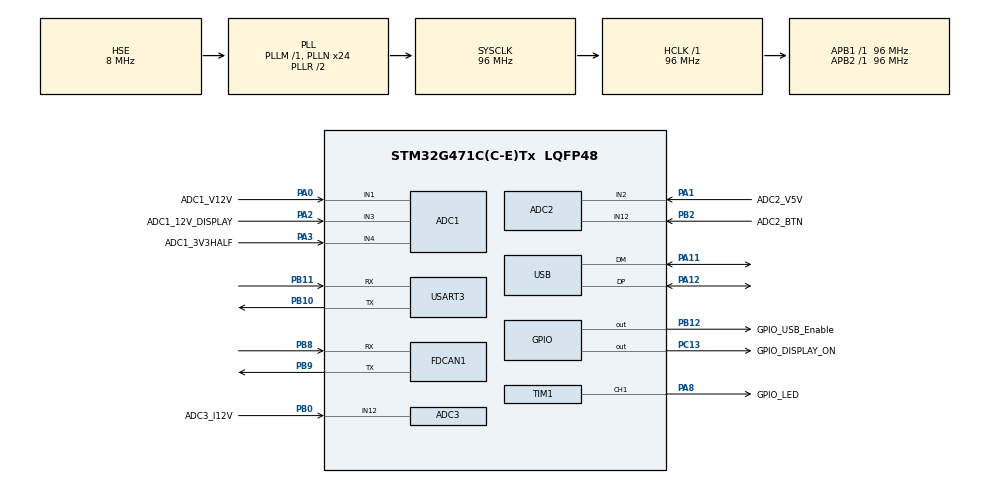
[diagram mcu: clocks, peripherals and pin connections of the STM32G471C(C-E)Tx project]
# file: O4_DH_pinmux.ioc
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ADC1.Channel-0\#ChannelRegularConversion=ADC_CHANNEL_1
ADC1.Channel-1\#ChannelRegularConversion=ADC_CHANNEL_3
ADC1.Channel-2\#ChannelRegularConversion=ADC_CHANNEL_4
ADC1.ClockPrescaler=ADC_CLOCK_ASYNC_DIV4
ADC1.ContinuousConvMode=DISABLE
ADC1.DMAContinuousRequests=ENABLE
ADC1.DataAlign=ADC_DATAALIGN_RIGHT
ADC1.EOCSelection=ADC_EOC_SINGLE_CONV
ADC1.ExternalTrigConv=ADC_EXTERNALTRIG_T1_TRGO
ADC1.ExternalTrigConvEdge=ADC_EXTERNALTRIGCONVEDGE_RISINGFALLING
ADC1.Mode=ADC_MODE_INDEPENDENT
ADC1.NbrOfConversion=3
ADC1.NbrOfConversionFlag=1
ADC1.OffsetNumber-0\#ChannelRegularConversion=ADC_OFFSET_NONE
ADC1.OffsetNumber-1\#ChannelRegularConversion=ADC_OFFSET_NONE
ADC1.OffsetNumber-2\#ChannelRegularConversion=ADC_OFFSET_NONE
ADC1.Overrun=ADC_OVR_DATA_OVERWRITTEN
ADC1.Rank-0\#ChannelRegularConversion=1
ADC1.Rank-1\#ChannelRegularConversion=2
ADC1.Rank-2\#ChannelRegularConversion=3
ADC1.SamplingTime-0\#ChannelRegularConversion=ADC_SAMPLETIME_92CYCLES_5
ADC1.SamplingTime-1\#ChannelRegularConversion=ADC_SAMPLETIME_92CYCLES_5
ADC1.SamplingTime-2\#ChannelRegularConversion=ADC_SAMPLETIME_92CYCLES_5
ADC1.master=1
ADC2.Channel-0\#ChannelRegularConversion=ADC_CHANNEL_2
ADC2.Channel-1\#ChannelRegularConversion=ADC_CHANNEL_12
ADC2.ClockPrescaler=ADC_CLOCK_ASYNC_DIV4
ADC2.ContinuousConvMode=DISABLE
ADC2.DMAContinuousRequests=ENABLE
ADC2.DataAlign=ADC_DATAALIGN_RIGHT
ADC2.EOCSelection=ADC_EOC_SINGLE_CONV
ADC2.ExternalTrigConv=ADC_EXTERNALTRIG_T1_TRGO
ADC2.ExternalTrigConvEdge=ADC_EXTERNALTRIGCONVEDGE_RISINGFALLING
ADC2.NbrOfConversion=2
ADC2.NbrOfConversionFlag=1
ADC2.OffsetNumber-0\#ChannelRegularConversion=ADC_OFFSET_NONE
ADC2.OffsetNumber-1\#ChannelRegularConversion=ADC_OFFSET_NONE
ADC2.Overrun=ADC_OVR_DATA_OVERWRITTEN
ADC2.Rank-0\#ChannelRegularConversion=1
ADC2.Rank-1\#ChannelRegularConversion=2
ADC2.SamplingTime-0\#ChannelRegularConversion=ADC_SAMPLETIME_92CYCLES_5
ADC2.SamplingTime-1\#ChannelRegularConversion=ADC_SAMPLETIME_92CYCLES_5
ADC3.Channel-0\#ChannelRegularConversion=ADC_CHANNEL_12
ADC3.Channel-1\#ChannelRegularConversion=ADC_CHANNEL_VBAT
ADC3.Channel-2\#ChannelRegularConversion=ADC_CHANNEL_VREFINT
ADC3.ClockPrescaler=ADC_CLOCK_ASYNC_DIV4
ADC3.ContinuousConvMode=DISABLE
ADC3.DMAContinuousRequests=ENABLE
ADC3.EOCSelection=ADC_EOC_SINGLE_CONV
ADC3.ExternalTrigConv=ADC_EXTERNALTRIG_T1_TRGO
ADC3.ExternalTrigConvEdge=ADC_EXTERNALTRIGCONVEDGE_RISINGFALLING
ADC3.NbrOfConversion=3
ADC3.NbrOfConversionFlag=1
ADC3.OffsetNumber-0\#ChannelRegularConversion=ADC_OFFSET_NONE
ADC3.OffsetNumber-1\#ChannelRegularConversion=ADC_OFFSET_NONE
ADC3.OffsetNumber-2\#ChannelRegularConversion=ADC_OFFSET_NONE
ADC3.Overrun=ADC_OVR_DATA_OVERWRITTEN
ADC3.Rank-0\#ChannelRegularConversion=1
ADC3.Rank-1\#ChannelRegularConversion=2
ADC3.Rank-2\#ChannelRegularConversion=3
ADC3.SamplingTime-0\#ChannelRegularConversion=ADC_SAMPLETIME_92CYCLES_5
ADC3.SamplingTime-1\#ChannelRegularConversion=ADC_SAMPLETIME_92CYCLES_5
ADC3.SamplingTime-2\#ChannelRegularConversion=ADC_SAMPLETIME_92CYCLES_5
ADC3.master=1
Dma.ADC1.0.Direction=DMA_PERIPH_TO_MEMORY
Dma.ADC1.0.EventEnable=ENABLE
Dma.ADC1.0.Instance=DMA1_Channel1
Dma.ADC1.0.MemDataAlignment=DMA_MDATAALIGN_HALFWORD
Dma.ADC1.0.MemInc=DMA_MINC_ENABLE
Dma.ADC1.0.Mode=DMA_CIRCULAR
Dma.ADC1.0.PeriphDataAlignment=DMA_PDATAALIGN_HALFWORD
Dma.ADC1.0.PeriphInc=DMA_PINC_DISABLE
Dma.ADC1.0.Polarity=HAL_DMAMUX_REQ_GEN_RISING
Dma.ADC1.0.Priority=DMA_PRIORITY_LOW
Dma.ADC1.0.RequestNumber=1
Dma.ADC1.0.SignalID=NONE
Dma.ADC1.0.SyncEnable=DISABLE
Dma.ADC1.0.SyncPolarity=HAL_DMAMUX_SYNC_NO_EVENT
Dma.ADC1.0.SyncRequestNumber=1
Dma.ADC1.0.SyncSignalID=NONE
Dma.ADC2.1.Direction=DMA_PERIPH_TO_MEMORY
Dma.ADC2.1.EventEnable=ENABLE
Dma.ADC2.1.Instance=DMA1_Channel2
Dma.ADC2.1.MemDataAlignment=DMA_MDATAALIGN_HALFWORD
Dma.ADC2.1.MemInc=DMA_MINC_ENABLE
Dma.ADC2.1.Mode=DMA_CIRCULAR
Dma.ADC2.1.PeriphDataAlignment=DMA_PDATAALIGN_HALFWORD
Dma.ADC2.1.PeriphInc=DMA_PINC_DISABLE
Dma.ADC2.1.Polarity=HAL_DMAMUX_REQ_GEN_RISING
Dma.ADC2.1.Priority=DMA_PRIORITY_LOW
Dma.ADC2.1.RequestNumber=1
Dma.ADC2.1.SignalID=NONE
Dma.ADC2.1.SyncEnable=DISABLE
Dma.ADC2.1.SyncPolarity=HAL_DMAMUX_SYNC_NO_EVENT
Dma.ADC2.1.SyncRequestNumber=1
Dma.ADC2.1.SyncSignalID=NONE
Dma.ADC3.2.Direction=DMA_PERIPH_TO_MEMORY
Dma.ADC3.2.EventEnable=DISABLE
Dma.ADC3.2.Instance=DMA1_Channel3
Dma.ADC3.2.MemDataAlignment=DMA_MDATAALIGN_HALFWORD
Dma.ADC3.2.MemInc=DMA_MINC_ENABLE
Dma.ADC3.2.Mode=DMA_CIRCULAR
Dma.ADC3.2.PeriphDataAlignment=DMA_PDATAALIGN_HALFWORD
Dma.ADC3.2.PeriphInc=DMA_PINC_DISABLE
Dma.ADC3.2.Polarity=HAL_DMAMUX_REQ_GEN_RISING
Dma.ADC3.2.Priority=DMA_PRIORITY_LOW
Dma.ADC3.2.RequestNumber=1
Dma.ADC3.2.SignalID=NONE
Dma.ADC3.2.SyncEnable=DISABLE
Dma.ADC3.2.SyncPolarity=HAL_DMAMUX_SYNC_NO_EVENT
Dma.ADC3.2.SyncRequestNumber=1
Dma.ADC3.2.SyncSignalID=NONE
Dma.Request0=ADC1
Dma.Request1=ADC2
Dma.Request2=ADC3
Mcu.Family=STM32G4
Mcu.Name=STM32G471C(C-E)Tx
Mcu.Package=LQFP48
NVIC.DMA1_Channel1_IRQn=true\:0\:0\:false\:false\:true\:false\:true
NVIC.DMA1_Channel2_IRQn=true\:0\:0\:false\:false\:true\:false\:true
NVIC.DMA1_Channel3_IRQn=true\:0\:0\:false\:false\:true\:false\:true
NVIC.DMAMUX_OVR_IRQn=true\:0\:0\:false\:false\:true\:false\:true
NVIC.PriorityGroup=NVIC_PRIORITYGROUP_4
NVIC.USB_LP_IRQn=true\:0\:0\:false\:false\:true\:false\:true
PA0.GPIO_Label=ADC1_V12V
PA0.Mode=IN1-Single-Ended
PA0.Signal=ADC1_IN1
PA1.GPIO_Label=ADC2_V5V
PA1.Mode=IN2-Single-Ended
PA1.Signal=ADC2_IN2
PA10.Signal=UCPD1_DBCC2
PA11.Mode=Device
PA11.Signal=USB_DM
PA12.Mode=Device
PA12.Signal=USB_DP
PA13.Mode=Trace_Asynchronous_SW
PA13.Signal=SYS_JTMS-SWDIO
PA14.Mode=Trace_Asynchronous_SW
PA14.Signal=SYS_JTCK-SWCLK
PA2.GPIO_Label=ADC1_12V_DISPLAY
PA2.Mode=IN3-Single-Ended
PA2.Signal=ADC1_IN3
PA3.GPIO_Label=ADC1_3V3HALF
PA3.Mode=IN4-Single-Ended
PA3.Signal=ADC1_IN4
PA8.GPIO_Label=GPIO_LED
PA8.Signal=S_TIM1_CH1
PA9.Signal=UCPD1_DBCC1
PB0.GPIO_Label=ADC3_I12V
PB0.Mode=IN12-Single-Ended
PB0.Signal=ADC3_IN12
PB10.Mode=Asynchronous
PB10.Signal=USART3_TX
PB11.Mode=Asynchronous
PB11.Signal=USART3_RX
PB12.GPIO_Label=GPIO_USB_Enable
PB12.Signal=GPIO_Output
PB2.GPIO_Label=ADC2_BTN
PB2.Mode=IN12-Single-Ended
PB2.Signal=ADC2_IN12
PB3.Mode=Trace_Asynchronous_SW
PB3.Signal=SYS_JTDO-SWO
PB4.Signal=UCPD1_CC2
PB6.Signal=UCPD1_CC1
PB8-BOOT0.Mode=FDCANFD
PB8-BOOT0.Signal=FDCAN1_RX
PB9.Mode=FDCANFD
PB9.Signal=FDCAN1_TX
PC13.GPIO_Label=GPIO_DISPLAY_ON
PC13.Signal=GPIO_Output
PF0-OSC_IN.Mode=HSE-External-Oscillator
PF0-OSC_IN.Signal=RCC_OSC_IN
PF1-OSC_OUT.Mode=HSE-External-Oscillator
PF1-OSC_OUT.Signal=RCC_OSC_OUT
ProjectManager.HeapSize=0x200
ProjectManager.StackSize=0x400
ProjectManager.TargetToolchain=STM32CubeIDE
RCC.ADC12CLockSelection=RCC_ADC12CLKSOURCE_PLL
RCC.ADC12Freq_Value=24000000
RCC.ADC345CLockSelection=RCC_ADC345CLKSOURCE_PLL
RCC.ADC345Freq_Value=24000000
RCC.AHBFreq_Value=96000000
RCC.APB1Freq_Value=96000000
RCC.APB1TimFreq_Value=96000000
RCC.APB2Freq_Value=96000000
RCC.APB2TimFreq_Value=96000000
RCC.CortexFreq_Value=96000000
RCC.EXTERNAL_CLOCK_VALUE=12288000
RCC.FDCANCLockSelection=RCC_FDCANCLKSOURCE_PLL
RCC.HCLKFreq_Value=96000000
RCC.HSE_VALUE=8000000
RCC.HSI48_VALUE=48000000
RCC.HSI_VALUE=16000000
RCC.LSE_VALUE=32768
RCC.PLLN=24
RCC.PLLP=RCC_PLLP_DIV8
RCC.PLLQ=RCC_PLLQ_DIV4
RCC.PLLSourceVirtual=RCC_PLLSOURCE_HSE
RCC.SYSCLKFreq_VALUE=96000000
RCC.SYSCLKSource=RCC_SYSCLKSOURCE_PLLCLK
RCC.USBFreq_Value=48000000
RCC.VCOOutputFreq_Value=192000000
SH.S_TIM1_CH1.0=TIM1_CH1,PWM Generation1 CH1
SYS.VoltageScaling=SYSCFG_VREFBUF_VOLTAGE_SCALE1
TIM1.AutoReloadPreload=TIM_AUTORELOAD_PRELOAD_ENABLE
TIM1.Channel-PWM\ Generation1\ CH1=TIM_CHANNEL_1
TIM1.CounterMode=TIM_COUNTERMODE_CENTERALIGNED1
TIM1.PeriodNoDither=7353
TIM1.Prescaler=32
TIM1.PulseNoDither_1=234
TIM1.TIM_MasterOutputTrigger=TIM_TRGO_UPDATE
TIM1.TIM_MasterOutputTrigger2=TIM_TRGO2_UPDATE
TIM1.TIM_MasterSlaveMode=TIM_MASTERSLAVEMODE_DISABLE
USART3.VirtualMode-Asynchronous=VM_ASYNC
USB_DEVICE.CLASS_NAME_FS=CDC
USB_DEVICE.VirtualMode=Cdc
USB_DEVICE.VirtualModeFS=Cdc_FS
VP_ADC3_Vbat_Input.Mode=IN-Vbat
VP_ADC3_Vref_Input.Mode=IN-Vrefint
VP_DAC1_VS_DACI1.Mode=DAC_OUT1_Int
VP_SYS_VS_DBSignals.Mode=DisableDeadBatterySignals
VP_TIM1_VS_ClockSourceINT.Mode=Internal
VP_USB_DEVICE_VS_USB_DEVICE_CDC_FS.Mode=CDC_FS
VREF+.Mode=InternalMode
VREF+.Signal=VREFBUF_OUT
board=custom

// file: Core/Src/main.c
/* USER CODE BEGIN Header */
/**
  ******************************************************************************
  * @file           : main.c
  * @brief          : Main program body
  ******************************************************************************
  * @attention
  *
  * <h2><center>&copy; Copyright (c) 2020 STMicroelectronics.
  * All rights reserved.</center></h2>
  *
  * This software component is licensed by ST under BSD 3-Clause license,
  * the "License"; You may not use this file except in compliance with the
  * License. You may obtain a copy of the License at:
  *                        opensource.org/licenses/BSD-3-Clause
  *
  ******************************************************************************
  */
/* USER CODE END Header */

#include "main.h"
#include "usb_device.h"
#include "adc.h"

ADC_HandleTypeDef hadc1;
ADC_HandleTypeDef hadc2;
ADC_HandleTypeDef hadc3;
DMA_HandleTypeDef hdma_adc1;
DMA_HandleTypeDef hdma_adc2;
DMA_HandleTypeDef hdma_adc3;

DAC_HandleTypeDef hdac1;

FDCAN_HandleTypeDef hfdcan1;

TIM_HandleTypeDef htim1;

UART_HandleTypeDef huart3;

void SystemClock_Config(void);
static void MX_GPIO_Init(void);
static void MX_DMA_Init(void);
static void MX_ADC1_Init(void);
static void MX_ADC2_Init(void);
static void MX_ADC3_Init(void);
static void MX_DAC1_Init(void);
static void MX_FDCAN1_Init(void);
static void MX_TIM1_Init(void);
static void MX_USART3_UART_Init(void);

/* USER CODE BEGIN 0 */

/* ToDo move later in separate file */
/* USER CODE END 0 */
void adc_start()
{
	if (HAL_ADCEx_Calibration_Start(&hadc1, ADC_SINGLE_ENDED) != HAL_OK)
	{
		Error_Handler();
	}
	if (HAL_ADCEx_Calibration_Start(&hadc2, ADC_SINGLE_ENDED) != HAL_OK)
	{
		Error_Handler();
	}
	if (HAL_ADCEx_Calibration_Start(&hadc3, ADC_SINGLE_ENDED) != HAL_OK)
	{
		Error_Handler();
	}
	HAL_Delay(100);
	HAL_ADC_Start_DMA(&hadc1, (uint32_t*)get_adc_raw_data(1,0), 3 );
	HAL_ADC_Start_DMA(&hadc2, (uint32_t*)get_adc_raw_data(2,0), 2 );
	HAL_ADC_Start_DMA(&hadc3, (uint32_t*)get_adc_raw_data(3,0), 3 );
}

int main(void)
{

  /* MCU Configuration--------------------------------------------------------*/

  /* Reset of all peripherals, Initializes the Flash interface and the Systick. */
  HAL_Init();

  /* USER CODE BEGIN Init */
  HAL_Delay(300); //delay after enable Vref
  /* USER CODE END Init */

  /* Configure the system clock */
  SystemClock_Config();

  /* Initialize all configured peripherals */
  MX_GPIO_Init();
  MX_DMA_Init();
  MX_ADC1_Init();
  MX_ADC2_Init();
  MX_ADC3_Init();
  MX_DAC1_Init();
  MX_FDCAN1_Init();
  MX_TIM1_Init();
  MX_USART3_UART_Init();
  MX_USB_Device_Init();
  /* USER CODE BEGIN 2 */
  /**/
  adc_start();
  /*## Start PWM signals generation #######################################*/
    /* Start channel 1 */
    if (HAL_TIM_PWM_Start(&htim1, TIM_CHANNEL_1) != HAL_OK)
    {
      /* PWM Generation Error */
      Error_Handler();
    }
    htim1.Instance->CCR1=7353/2;

  /* USER CODE END 2 */

  /* Infinite loop */
  /* USER CODE BEGIN WHILE */
    uint32_t i,s=0;
  while (1)
  {
	  i++;
	  s+=i;
    /* USER CODE END WHILE */

  }
}

void SystemClock_Config(void)
{
  RCC_OscInitTypeDef RCC_OscInitStruct = {0};
  RCC_ClkInitTypeDef RCC_ClkInitStruct = {0};
  RCC_PeriphCLKInitTypeDef PeriphClkInit = {0};

  /** Configure the main internal regulator output voltage
  */
  HAL_PWREx_ControlVoltageScaling(PWR_REGULATOR_VOLTAGE_SCALE1);
  /** Initializes the CPU, AHB and APB busses clocks
  */
  RCC_OscInitStruct.OscillatorType = RCC_OSCILLATORTYPE_HSE;
  RCC_OscInitStruct.HSEState = RCC_HSE_ON;
  RCC_OscInitStruct.PLL.PLLState = RCC_PLL_ON;
  RCC_OscInitStruct.PLL.PLLSource = RCC_PLLSOURCE_HSE;
  RCC_OscInitStruct.PLL.PLLM = RCC_PLLM_DIV1;
  RCC_OscInitStruct.PLL.PLLN = 24;
  RCC_OscInitStruct.PLL.PLLP = RCC_PLLP_DIV8;
  RCC_OscInitStruct.PLL.PLLQ = RCC_PLLQ_DIV4;
  RCC_OscInitStruct.PLL.PLLR = RCC_PLLR_DIV2;
  if (HAL_RCC_OscConfig(&RCC_OscInitStruct) != HAL_OK)
  {
    Error_Handler();
  }
  /** Initializes the CPU, AHB and APB busses clocks
  */
  RCC_ClkInitStruct.ClockType = RCC_CLOCKTYPE_HCLK|RCC_CLOCKTYPE_SYSCLK
                              |RCC_CLOCKTYPE_PCLK1|RCC_CLOCKTYPE_PCLK2;
  RCC_ClkInitStruct.SYSCLKSource = RCC_SYSCLKSOURCE_PLLCLK;
  RCC_ClkInitStruct.AHBCLKDivider = RCC_SYSCLK_DIV1;
  RCC_ClkInitStruct.APB1CLKDivider = RCC_HCLK_DIV1;
  RCC_ClkInitStruct.APB2CLKDivider = RCC_HCLK_DIV1;

  if (HAL_RCC_ClockConfig(&RCC_ClkInitStruct, FLASH_LATENCY_4) != HAL_OK)
  {
    Error_Handler();
  }
  /** Initializes the peripherals clocks
  */
  PeriphClkInit.PeriphClockSelection = RCC_PERIPHCLK_USART3|RCC_PERIPHCLK_USB
                              |RCC_PERIPHCLK_ADC12|RCC_PERIPHCLK_ADC345
                              |RCC_PERIPHCLK_FDCAN;
  PeriphClkInit.Usart3ClockSelection = RCC_USART3CLKSOURCE_PCLK1;
  PeriphClkInit.FdcanClockSelection = RCC_FDCANCLKSOURCE_PLL;
  PeriphClkInit.UsbClockSelection = RCC_USBCLKSOURCE_PLL;
  PeriphClkInit.Adc12ClockSelection = RCC_ADC12CLKSOURCE_PLL;
  PeriphClkInit.Adc345ClockSelection = RCC_ADC345CLKSOURCE_PLL;
  if (HAL_RCCEx_PeriphCLKConfig(&PeriphClkInit) != HAL_OK)
  {
    Error_Handler();
  }
}

static void MX_ADC1_Init(void)
{

  ADC_MultiModeTypeDef multimode = {0};
  ADC_ChannelConfTypeDef sConfig = {0};

  /** Common config
  */
  hadc1.Instance = ADC1;
  hadc1.Init.ClockPrescaler = ADC_CLOCK_ASYNC_DIV4;
  hadc1.Init.Resolution = ADC_RESOLUTION_12B;
  hadc1.Init.DataAlign = ADC_DATAALIGN_RIGHT;
  hadc1.Init.GainCompensation = 0;
  hadc1.Init.ScanConvMode = ADC_SCAN_ENABLE;
  hadc1.Init.EOCSelection = ADC_EOC_SINGLE_CONV;
  hadc1.Init.LowPowerAutoWait = DISABLE;
  hadc1.Init.ContinuousConvMode = DISABLE;
  hadc1.Init.NbrOfConversion = 3;
  hadc1.Init.DiscontinuousConvMode = DISABLE;
  hadc1.Init.ExternalTrigConv = ADC_EXTERNALTRIG_T1_TRGO;
  hadc1.Init.ExternalTrigConvEdge = ADC_EXTERNALTRIGCONVEDGE_RISINGFALLING;
  hadc1.Init.DMAContinuousRequests = ENABLE;
  hadc1.Init.Overrun = ADC_OVR_DATA_OVERWRITTEN;
  hadc1.Init.OversamplingMode = DISABLE;
  if (HAL_ADC_Init(&hadc1) != HAL_OK)
  {
    Error_Handler();
  }
  /** Configure the ADC multi-mode
  */
  multimode.Mode = ADC_MODE_INDEPENDENT;
  if (HAL_ADCEx_MultiModeConfigChannel(&hadc1, &multimode) != HAL_OK)
  {
    Error_Handler();
  }
  /** Configure Regular Channel
  */
  sConfig.Channel = ADC_CHANNEL_1;
  sConfig.Rank = ADC_REGULAR_RANK_1;
  sConfig.SamplingTime = ADC_SAMPLETIME_92CYCLES_5;
  sConfig.SingleDiff = ADC_SINGLE_ENDED;
  sConfig.OffsetNumber = ADC_OFFSET_NONE;
  sConfig.Offset = 0;
  if (HAL_ADC_ConfigChannel(&hadc1, &sConfig) != HAL_OK)
  {
    Error_Handler();
  }
  /** Configure Regular Channel
  */
  sConfig.Channel = ADC_CHANNEL_3;
  sConfig.Rank = ADC_REGULAR_RANK_2;
  if (HAL_ADC_ConfigChannel(&hadc1, &sConfig) != HAL_OK)
  {
    Error_Handler();
  }
  /** Configure Regular Channel
  */
  sConfig.Channel = ADC_CHANNEL_4;
  sConfig.Rank = ADC_REGULAR_RANK_3;
  if (HAL_ADC_ConfigChannel(&hadc1, &sConfig) != HAL_OK)
  {
    Error_Handler();
  }

}

static void MX_ADC2_Init(void)
{

  ADC_ChannelConfTypeDef sConfig = {0};

  /** Common config
  */
  hadc2.Instance = ADC2;
  hadc2.Init.ClockPrescaler = ADC_CLOCK_ASYNC_DIV4;
  hadc2.Init.Resolution = ADC_RESOLUTION_12B;
  hadc2.Init.DataAlign = ADC_DATAALIGN_RIGHT;
  hadc2.Init.GainCompensation = 0;
  hadc2.Init.ScanConvMode = ADC_SCAN_ENABLE;
  hadc2.Init.EOCSelection = ADC_EOC_SINGLE_CONV;
  hadc2.Init.LowPowerAutoWait = DISABLE;
  hadc2.Init.ContinuousConvMode = DISABLE;
  hadc2.Init.NbrOfConversion = 2;
  hadc2.Init.DiscontinuousConvMode = DISABLE;
  hadc2.Init.ExternalTrigConv = ADC_EXTERNALTRIG_T1_TRGO;
  hadc2.Init.ExternalTrigConvEdge = ADC_EXTERNALTRIGCONVEDGE_RISINGFALLING;
  hadc2.Init.DMAContinuousRequests = ENABLE;
  hadc2.Init.Overrun = ADC_OVR_DATA_OVERWRITTEN;
  hadc2.Init.OversamplingMode = DISABLE;
  if (HAL_ADC_Init(&hadc2) != HAL_OK)
  {
    Error_Handler();
  }
  /** Configure Regular Channel
  */
  sConfig.Channel = ADC_CHANNEL_2;
  sConfig.Rank = ADC_REGULAR_RANK_1;
  sConfig.SamplingTime = ADC_SAMPLETIME_92CYCLES_5;
  sConfig.SingleDiff = ADC_SINGLE_ENDED;
  sConfig.OffsetNumber = ADC_OFFSET_NONE;
  sConfig.Offset = 0;
  if (HAL_ADC_ConfigChannel(&hadc2, &sConfig) != HAL_OK)
  {
    Error_Handler();
  }
  /** Configure Regular Channel
  */
  sConfig.Channel = ADC_CHANNEL_12;
  sConfig.Rank = ADC_REGULAR_RANK_2;
  if (HAL_ADC_ConfigChannel(&hadc2, &sConfig) != HAL_OK)
  {
    Error_Handler();
  }

}

static void MX_ADC3_Init(void)
{

  ADC_MultiModeTypeDef multimode = {0};
  ADC_ChannelConfTypeDef sConfig = {0};

  /** Common config
  */
  hadc3.Instance = ADC3;
  hadc3.Init.ClockPrescaler = ADC_CLOCK_ASYNC_DIV4;
  hadc3.Init.Resolution = ADC_RESOLUTION_12B;
  hadc3.Init.DataAlign = ADC_DATAALIGN_RIGHT;
  hadc3.Init.GainCompensation = 0;
  hadc3.Init.ScanConvMode = ADC_SCAN_ENABLE;
  hadc3.Init.EOCSelection = ADC_EOC_SINGLE_CONV;
  hadc3.Init.LowPowerAutoWait = DISABLE;
  hadc3.Init.ContinuousConvMode = DISABLE;
  hadc3.Init.NbrOfConversion = 3;
  hadc3.Init.DiscontinuousConvMode = DISABLE;
  hadc3.Init.ExternalTrigConv = ADC_EXTERNALTRIG_T1_TRGO;
  hadc3.Init.ExternalTrigConvEdge = ADC_EXTERNALTRIGCONVEDGE_RISINGFALLING;
  hadc3.Init.DMAContinuousRequests = ENABLE;
  hadc3.Init.Overrun = ADC_OVR_DATA_OVERWRITTEN;
  hadc3.Init.OversamplingMode = DISABLE;
  if (HAL_ADC_Init(&hadc3) != HAL_OK)
  {
    Error_Handler();
  }
  /** Configure the ADC multi-mode
  */
  multimode.Mode = ADC_MODE_INDEPENDENT;
  if (HAL_ADCEx_MultiModeConfigChannel(&hadc3, &multimode) != HAL_OK)
  {
    Error_Handler();
  }
  /** Configure Regular Channel
  */
  sConfig.Channel = ADC_CHANNEL_12;
  sConfig.Rank = ADC_REGULAR_RANK_1;
  sConfig.SamplingTime = ADC_SAMPLETIME_92CYCLES_5;
  sConfig.SingleDiff = ADC_SINGLE_ENDED;
  sConfig.OffsetNumber = ADC_OFFSET_NONE;
  sConfig.Offset = 0;
  if (HAL_ADC_ConfigChannel(&hadc3, &sConfig) != HAL_OK)
  {
    Error_Handler();
  }
  /** Configure Regular Channel
  */
  sConfig.Channel = ADC_CHANNEL_VBAT;
  sConfig.Rank = ADC_REGULAR_RANK_2;
  if (HAL_ADC_ConfigChannel(&hadc3, &sConfig) != HAL_OK)
  {
    Error_Handler();
  }
  /** Configure Regular Channel
  */
  sConfig.Channel = ADC_CHANNEL_VREFINT;
  sConfig.Rank = ADC_REGULAR_RANK_3;
  if (HAL_ADC_ConfigChannel(&hadc3, &sConfig) != HAL_OK)
  {
    Error_Handler();
  }

}

static void MX_DAC1_Init(void)
{

  DAC_ChannelConfTypeDef sConfig = {0};

  /** DAC Initialization
  */
  hdac1.Instance = DAC1;
  if (HAL_DAC_Init(&hdac1) != HAL_OK)
  {
    Error_Handler();
  }
  /** DAC channel OUT1 config
  */
  sConfig.DAC_HighFrequency = DAC_HIGH_FREQUENCY_INTERFACE_MODE_AUTOMATIC;
  sConfig.DAC_DMADoubleDataMode = DISABLE;
  sConfig.DAC_SignedFormat = DISABLE;
  sConfig.DAC_SampleAndHold = DAC_SAMPLEANDHOLD_DISABLE;
  sConfig.DAC_Trigger = DAC_TRIGGER_NONE;
  sConfig.DAC_Trigger2 = DAC_TRIGGER_NONE;
  sConfig.DAC_OutputBuffer = DAC_OUTPUTBUFFER_DISABLE;
  sConfig.DAC_ConnectOnChipPeripheral = DAC_CHIPCONNECT_ENABLE;
  sConfig.DAC_UserTrimming = DAC_TRIMMING_FACTORY;
  if (HAL_DAC_ConfigChannel(&hdac1, &sConfig, DAC_CHANNEL_1) != HAL_OK)
  {
    Error_Handler();
  }

}

static void MX_FDCAN1_Init(void)
{

  hfdcan1.Instance = FDCAN1;
  hfdcan1.Init.ClockDivider = FDCAN_CLOCK_DIV1;
  hfdcan1.Init.FrameFormat = FDCAN_FRAME_FD_NO_BRS;
  hfdcan1.Init.Mode = FDCAN_MODE_NORMAL;
  hfdcan1.Init.AutoRetransmission = DISABLE;
  hfdcan1.Init.TransmitPause = DISABLE;
  hfdcan1.Init.ProtocolException = DISABLE;
  hfdcan1.Init.NominalPrescaler = 1;
  hfdcan1.Init.NominalSyncJumpWidth = 1;
  hfdcan1.Init.NominalTimeSeg1 = 2;
  hfdcan1.Init.NominalTimeSeg2 = 2;
  hfdcan1.Init.DataPrescaler = 1;
  hfdcan1.Init.DataSyncJumpWidth = 1;
  hfdcan1.Init.DataTimeSeg1 = 1;
  hfdcan1.Init.DataTimeSeg2 = 1;
  hfdcan1.Init.StdFiltersNbr = 0;
  hfdcan1.Init.ExtFiltersNbr = 0;
  hfdcan1.Init.TxFifoQueueMode = FDCAN_TX_FIFO_OPERATION;
  if (HAL_FDCAN_Init(&hfdcan1) != HAL_OK)
  {
    Error_Handler();
  }

}

static void MX_TIM1_Init(void)
{

  TIM_ClockConfigTypeDef sClockSourceConfig = {0};
  TIM_MasterConfigTypeDef sMasterConfig = {0};
  TIM_OC_InitTypeDef sConfigOC = {0};
  TIM_BreakDeadTimeConfigTypeDef sBreakDeadTimeConfig = {0};

  htim1.Instance = TIM1;
  htim1.Init.Prescaler = 32;
  htim1.Init.CounterMode = TIM_COUNTERMODE_CENTERALIGNED1;
  htim1.Init.Period = 7353;
  htim1.Init.ClockDivision = TIM_CLOCKDIVISION_DIV1;
  htim1.Init.RepetitionCounter = 0;
  htim1.Init.AutoReloadPreload = TIM_AUTORELOAD_PRELOAD_ENABLE;
  if (HAL_TIM_Base_Init(&htim1) != HAL_OK)
  {
    Error_Handler();
  }
  sClockSourceConfig.ClockSource = TIM_CLOCKSOURCE_INTERNAL;
  if (HAL_TIM_ConfigClockSource(&htim1, &sClockSourceConfig) != HAL_OK)
  {
    Error_Handler();
  }
  if (HAL_TIM_PWM_Init(&htim1) != HAL_OK)
  {
    Error_Handler();
  }
  sMasterConfig.MasterOutputTrigger = TIM_TRGO_UPDATE;
  sMasterConfig.MasterOutputTrigger2 = TIM_TRGO2_UPDATE;
  sMasterConfig.MasterSlaveMode = TIM_MASTERSLAVEMODE_DISABLE;
  if (HAL_TIMEx_MasterConfigSynchronization(&htim1, &sMasterConfig) != HAL_OK)
  {
    Error_Handler();
  }
  sConfigOC.OCMode = TIM_OCMODE_PWM1;
  sConfigOC.Pulse = 234;
  sConfigOC.OCPolarity = TIM_OCPOLARITY_HIGH;
  sConfigOC.OCNPolarity = TIM_OCNPOLARITY_HIGH;
  sConfigOC.OCFastMode = TIM_OCFAST_DISABLE;
  sConfigOC.OCIdleState = TIM_OCIDLESTATE_RESET;
  sConfigOC.OCNIdleState = TIM_OCNIDLESTATE_RESET;
  if (HAL_TIM_PWM_ConfigChannel(&htim1, &sConfigOC, TIM_CHANNEL_1) != HAL_OK)
  {
    Error_Handler();
  }
  sBreakDeadTimeConfig.OffStateRunMode = TIM_OSSR_DISABLE;
  sBreakDeadTimeConfig.OffStateIDLEMode = TIM_OSSI_DISABLE;
  sBreakDeadTimeConfig.LockLevel = TIM_LOCKLEVEL_OFF;
  sBreakDeadTimeConfig.DeadTime = 0;
  sBreakDeadTimeConfig.BreakState = TIM_BREAK_DISABLE;
  sBreakDeadTimeConfig.BreakPolarity = TIM_BREAKPOLARITY_HIGH;
  sBreakDeadTimeConfig.BreakFilter = 0;
  sBreakDeadTimeConfig.BreakAFMode = TIM_BREAK_AFMODE_INPUT;
  sBreakDeadTimeConfig.Break2State = TIM_BREAK2_DISABLE;
  sBreakDeadTimeConfig.Break2Polarity = TIM_BREAK2POLARITY_HIGH;
  sBreakDeadTimeConfig.Break2Filter = 0;
  sBreakDeadTimeConfig.Break2AFMode = TIM_BREAK_AFMODE_INPUT;
  sBreakDeadTimeConfig.AutomaticOutput = TIM_AUTOMATICOUTPUT_DISABLE;
  if (HAL_TIMEx_ConfigBreakDeadTime(&htim1, &sBreakDeadTimeConfig) != HAL_OK)
  {
    Error_Handler();
  }
  HAL_TIM_MspPostInit(&htim1);

}

static void MX_USART3_UART_Init(void)
{

  huart3.Instance = USART3;
  huart3.Init.BaudRate = 115200;
  huart3.Init.WordLength = UART_WORDLENGTH_8B;
  huart3.Init.StopBits = UART_STOPBITS_1;
  huart3.Init.Parity = UART_PARITY_NONE;
  huart3.Init.Mode = UART_MODE_TX_RX;
  huart3.Init.HwFlowCtl = UART_HWCONTROL_NONE;
  huart3.Init.OverSampling = UART_OVERSAMPLING_16;
  huart3.Init.OneBitSampling = UART_ONE_BIT_SAMPLE_DISABLE;
  huart3.Init.ClockPrescaler = UART_PRESCALER_DIV1;
  huart3.AdvancedInit.AdvFeatureInit = UART_ADVFEATURE_NO_INIT;
  if (HAL_UART_Init(&huart3) != HAL_OK)
  {
    Error_Handler();
  }
  if (HAL_UARTEx_SetTxFifoThreshold(&huart3, UART_TXFIFO_THRESHOLD_1_8) != HAL_OK)
  {
    Error_Handler();
  }
  if (HAL_UARTEx_SetRxFifoThreshold(&huart3, UART_RXFIFO_THRESHOLD_1_8) != HAL_OK)
  {
    Error_Handler();
  }
  if (HAL_UARTEx_DisableFifoMode(&huart3) != HAL_OK)
  {
    Error_Handler();
  }

}

static void MX_DMA_Init(void)
{

  /* DMA controller clock enable */
  __HAL_RCC_DMAMUX1_CLK_ENABLE();
  __HAL_RCC_DMA1_CLK_ENABLE();

  /* DMA interrupt init */
  /* DMA1_Channel1_IRQn interrupt configuration */
  HAL_NVIC_SetPriority(DMA1_Channel1_IRQn, 0, 0);
  HAL_NVIC_EnableIRQ(DMA1_Channel1_IRQn);
  /* DMA1_Channel2_IRQn interrupt configuration */
  HAL_NVIC_SetPriority(DMA1_Channel2_IRQn, 0, 0);
  HAL_NVIC_EnableIRQ(DMA1_Channel2_IRQn);
  /* DMA1_Channel3_IRQn interrupt configuration */
  HAL_NVIC_SetPriority(DMA1_Channel3_IRQn, 0, 0);
  HAL_NVIC_EnableIRQ(DMA1_Channel3_IRQn);
  /* DMAMUX_OVR_IRQn interrupt configuration */
  HAL_NVIC_SetPriority(DMAMUX_OVR_IRQn, 0, 0);
  HAL_NVIC_EnableIRQ(DMAMUX_OVR_IRQn);

}

static void MX_GPIO_Init(void)
{
  GPIO_InitTypeDef GPIO_InitStruct = {0};

  /* GPIO Ports Clock Enable */
  __HAL_RCC_GPIOC_CLK_ENABLE();
  __HAL_RCC_GPIOF_CLK_ENABLE();
  __HAL_RCC_GPIOA_CLK_ENABLE();
  __HAL_RCC_GPIOB_CLK_ENABLE();

  /*Configure GPIO pin Output Level */
  HAL_GPIO_WritePin(GPIO_DISPLAY_ON_GPIO_Port, GPIO_DISPLAY_ON_Pin, GPIO_PIN_RESET);

  /*Configure GPIO pin Output Level */
  HAL_GPIO_WritePin(GPIO_USB_Enable_GPIO_Port, GPIO_USB_Enable_Pin, GPIO_PIN_RESET);

  /*Configure GPIO pin : GPIO_DISPLAY_ON_Pin */
  GPIO_InitStruct.Pin = GPIO_DISPLAY_ON_Pin;
  GPIO_InitStruct.Mode = GPIO_MODE_OUTPUT_PP;
  GPIO_InitStruct.Pull = GPIO_NOPULL;
  GPIO_InitStruct.Speed = GPIO_SPEED_FREQ_LOW;
  HAL_GPIO_Init(GPIO_DISPLAY_ON_GPIO_Port, &GPIO_InitStruct);

  /*Configure GPIO pin : GPIO_USB_Enable_Pin */
  GPIO_InitStruct.Pin = GPIO_USB_Enable_Pin;
  GPIO_InitStruct.Mode = GPIO_MODE_OUTPUT_PP;
  GPIO_InitStruct.Pull = GPIO_NOPULL;
  GPIO_InitStruct.Speed = GPIO_SPEED_FREQ_LOW;
  HAL_GPIO_Init(GPIO_USB_Enable_GPIO_Port, &GPIO_InitStruct);

}

void Error_Handler(void)
{
}

/************************ (C) COPYRIGHT STMicroelectronics *****END OF FILE****/
